AUTOSAR XML (schema 314)
package /ComponentType
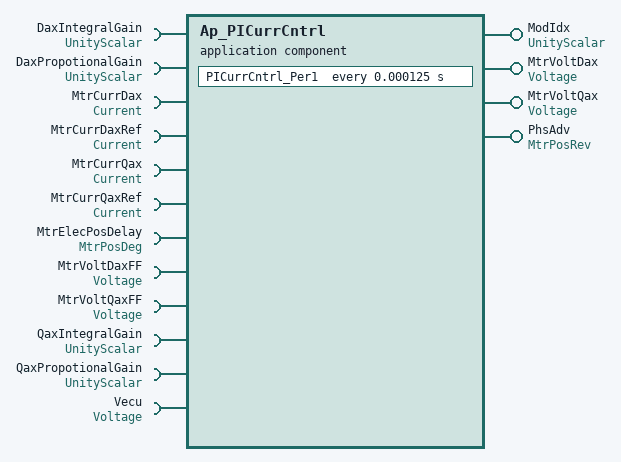
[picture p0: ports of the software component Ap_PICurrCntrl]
  application software component type Ap_PICurrCntrl  # PI Current Control
    4 x provide port:
      ModIdx: unqueued-sender-com-spec{data-element=Uls_f32, can-invalidate=false, init-value=D_ZERO_ULS_F32}, provided-interface=UnityScalar
      MtrVoltDax: unqueued-sender-com-spec{data-element=Volt_f32, can-invalidate=false, init-value=D_ZERO_ULS_F32}, provided-interface=Voltage
      MtrVoltQax: unqueued-sender-com-spec{data-element=Volt_f32, can-invalidate=false, init-value=D_ZERO_ULS_F32}, provided-interface=Voltage
      PhsAdv: unqueued-sender-com-spec{data-element=Rev_f32, can-invalidate=false, init-value=D_ZERO_ULS_F32}, provided-interface=MtrPosRev
    12 x require port:
      DaxIntegralGain: unqueued-receiver-com-spec{data-element=Uls_f32, init-value=D_ZERO_ULS_F32}, required-interface=UnityScalar
      DaxPropotionalGain: unqueued-receiver-com-spec{data-element=Uls_f32, init-value=D_ZERO_ULS_F32}, required-interface=UnityScalar
      MtrCurrDax: unqueued-receiver-com-spec{data-element=Amp_f32, init-value=D_ZERO_ULS_F32}, required-interface=Current
      MtrCurrDaxRef: unqueued-receiver-com-spec{data-element=Amp_f32, init-value=D_ZERO_ULS_F32}, required-interface=Current
      MtrCurrQax: unqueued-receiver-com-spec{data-element=Amp_f32, init-value=D_ZERO_ULS_F32}, required-interface=Current
      MtrCurrQaxRef: unqueued-receiver-com-spec{data-element=Amp_f32, init-value=D_ZERO_ULS_F32}, required-interface=Current
      MtrElecPosDelay: unqueued-receiver-com-spec{data-element=Deg_f32, init-value=D_ZERO_ULS_F32}, required-interface=MtrPosDeg
      MtrVoltDaxFF: unqueued-receiver-com-spec{data-element=Volt_f32, init-value=D_ZERO_ULS_F32}, required-interface=Voltage
      MtrVoltQaxFF: unqueued-receiver-com-spec{data-element=Volt_f32, init-value=D_ZERO_ULS_F32}, required-interface=Voltage
      QaxIntegralGain: unqueued-receiver-com-spec{data-element=Uls_f32, init-value=D_ZERO_ULS_F32}, required-interface=UnityScalar
      QaxPropotionalGain: unqueued-receiver-com-spec{data-element=Uls_f32, init-value=D_ZERO_ULS_F32}, required-interface=UnityScalar
      Vecu: unqueued-receiver-com-spec{data-element=Volt_f32, init-value=D_ZERO_ULS_F32}, required-interface=Voltage
  internal behavior Ap_PICurrCntrl_InternalBehavior: component=Ap_PICurrCntrl
    timing event TMT_PICurrCntrl_Per1: start-on-event=PICurrCntrl_Per1, period=0.000125
    port-api-options:
      enable-take-address=false, indirect-api=false, port=DaxIntegralGain
      enable-take-address=false, indirect-api=false, port=DaxPropotionalGain
      enable-take-address=false, indirect-api=false, port=ModIdx
      enable-take-address=false, indirect-api=false, port=MtrCurrDax
      enable-take-address=false, indirect-api=false, port=MtrCurrDaxRef
      enable-take-address=false, indirect-api=false, port=MtrCurrQax
      enable-take-address=false, indirect-api=false, port=MtrCurrQaxRef
      enable-take-address=false, indirect-api=false, port=MtrElecPosDelay
      enable-take-address=false, indirect-api=false, port=MtrVoltDax
      enable-take-address=false, indirect-api=false, port=MtrVoltDaxFF
      enable-take-address=false, indirect-api=false, port=MtrVoltQax
      enable-take-address=false, indirect-api=false, port=MtrVoltQaxFF
      enable-take-address=false, indirect-api=false, port=PhsAdv
      enable-take-address=false, indirect-api=false, port=QaxIntegralGain
      enable-take-address=false, indirect-api=false, port=QaxPropotionalGain
      enable-take-address=false, indirect-api=false, port=Vecu
    runnable PICurrCntrl_Per1
      12 x data read access:
        READ_DaxIntegralGain_Uls_f32: data-element=DaxIntegralGain.Uls_f32
        READ_DaxPropotionalGain_Uls_f32: data-element=DaxPropotionalGain.Uls_f32
        READ_MtrCurrDax_Amp_f32: data-element=MtrCurrDax.Amp_f32
        READ_MtrCurrDaxRef_Amp_f32: data-element=MtrCurrDaxRef.Amp_f32
        READ_MtrCurrQax_Amp_f32: data-element=MtrCurrQax.Amp_f32
        READ_MtrCurrQaxRef_Amp_f32: data-element=MtrCurrQaxRef.Amp_f32
        READ_MtrElecPosDelay_Deg_f32: data-element=MtrElecPosDelay.Deg_f32
        READ_MtrVoltDaxFF_Volt_f32: data-element=MtrVoltDaxFF.Volt_f32
        READ_MtrVoltQaxFF_Volt_f32: data-element=MtrVoltQaxFF.Volt_f32
        READ_QaxIntegralGain_Uls_f32: data-element=QaxIntegralGain.Uls_f32
        READ_QaxPropotionalGain_Uls_f32: data-element=QaxPropotionalGain.Uls_f32
        READ_Vecu_Volt_f32: data-element=Vecu.Volt_f32
      4 x data write access:
        WRITE_ModIdx_Uls_f32: data-element=ModIdx.Uls_f32
        WRITE_MtrVoltDax_Volt_f32: data-element=MtrVoltDax.Volt_f32
        WRITE_MtrVoltQax_Volt_f32: data-element=MtrVoltQax.Volt_f32
        WRITE_PhsAdv_Rev_f32: data-element=PhsAdv.Rev_f32
  swc implementation Ap_PICurrCntrl_Implementation: behavior=Ap_PICurrCntrl_InternalBehavior
    code-descriptors:
      code Code: type=SRC
